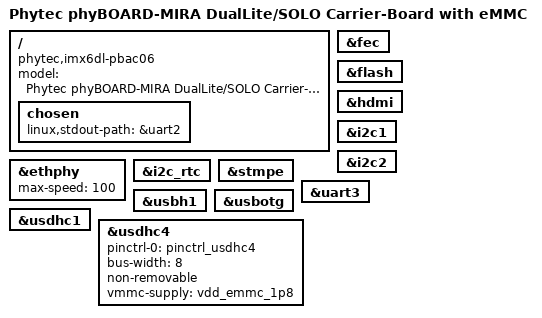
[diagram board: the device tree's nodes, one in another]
/*
 * Copyright (C) 2015 PHYTEC Messtechnik
 * Author: Stefan Christ <s.christ@phytec.de>
 *
 * The code contained herein is licensed under the GNU General Public
 * License. You may obtain a copy of the GNU General Public License
 * Version 2 or later at the following locations:
 *
 * http://www.opensource.org/licenses/gpl-license.html
 * http://www.gnu.org/copyleft/gpl.html
 */

/dts-v1/;
#include "imx6dl.dtsi"
#include "imx6qdl-phytec-phycore-som.dtsi"
#include "imx6qdl-phytec-mira.dtsi"
#include "imx6qdl-phytec-mira-peb-eval-01.dtsi"

/ {
	model = "Phytec phyBOARD-MIRA DualLite/SOLO Carrier-Board with eMMC";
	compatible = "phytec,imx6dl-pbac06", "phytec,imx6qdl-pcm058", "fsl,imx6dl";

	chosen {
		linux,stdout-path = &uart2;
	};
};

&ethphy {
	max-speed = <100>;
};

&fec {
	status = "okay";
};

&flash {
	status = "okay";
};

&hdmi {
	status = "okay";
};

&i2c1 {
	status = "okay";
};

&i2c2 {
	status = "okay";
};

&i2c_rtc {
	status = "okay";
};

&stmpe {
	status = "okay";
};

&uart3 {
	status = "okay";
};

&usbh1 {
	status = "okay";
};

&usbotg {
	status = "okay";
};

&usdhc1 {
	status = "okay";
};

&usdhc4 {
	pinctrl-names = "default";
	pinctrl-0 = <&pinctrl_usdhc4>;
	bus-width = <8>;
	non-removable;
	vmmc-supply = <&vdd_emmc_1p8>;
	status = "okay";
};
